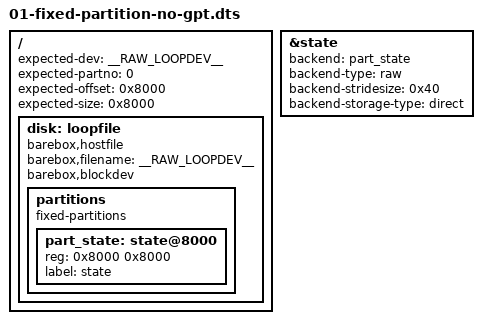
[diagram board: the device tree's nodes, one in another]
/dts-v1/;

#include "barebox-state.dtsi"

/ {
	expected-dev = __RAW_LOOPDEV__;
	expected-partno = <0>; /* unpartitioned space */
	expected-offset = <0x8000>;
	expected-size = <0x8000>;

	disk: loopfile {
		compatible = "barebox,hostfile";
		barebox,filename = __RAW_LOOPDEV__;
		barebox,blockdev;

		partitions {
			compatible = "fixed-partitions";
			#address-cells = <1>;
			#size-cells = <1>;

			part_state: state@8000 {
				reg = <0x8000 0x8000>;
				label = "state";
			};
		};
	};
};

&state {
	backend = <&part_state>;
	backend-type = "raw";
	backend-stridesize = <0x40>;
	backend-storage-type = "direct";
};
